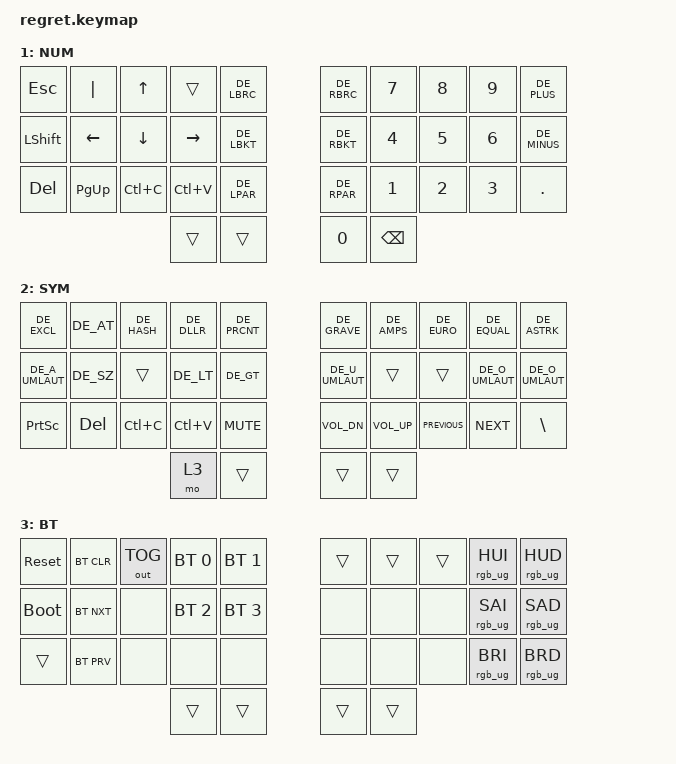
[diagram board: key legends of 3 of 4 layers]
#include <behaviors.dtsi>
#include <dt-bindings/zmk/keys.h>
#include <dt-bindings/zmk/rgb.h>
#include <dt-bindings/zmk/bt.h>
#include <dt-bindings/zmk/outputs.h>
#include <locale/keys_de.h>

#define BASE 0
#define NUM  1
#define NAV  2
#define DE   3


#define COMBO(NAME, BINDINGS, KEYPOS, LAYERS) \
combo_##NAME { \
    timeout-ms = <30>; \
    bindings = <BINDINGS>; \
    key-positions = <KEYPOS>; \
    layers = <LAYERS>; \
};


/ {
    chosen {
          zmk,battery = &vbatt;
    };

    vbatt: vbatt {
            compatible = "zmk,battery-nrf-vddh";
            label = "VBATT";
    };

    combos {
       compatible = "zmk,combos";
        /* Top corners (Q+P) = bootloader */
        combo_boot {
            key-positions = <0 9>;
            bindings = <&bootloader>;
        };
       
       combo_esc {
            timeout-ms = <50>;
            key-positions = <0 1>;
            bindings = <&kp ESC>;
       };
       combo_caps {
            timeout-ms = <50>;
            key-positions = <10 19>;
            bindings = <&caps_word>;
       };
       combo_singlequote {
            timeout-ms = <50>;
            key-positions = <7 8>;
            bindings = <&kp DE_SQT>;
       };
       combo_doublequote {
            timeout-ms = <50>;
            key-positions = <8 9>;
            bindings = <&kp DE_DQT>;
       };
       combo_minus {
            timeout-ms = <50>;
            key-positions = <17 18>;
            bindings = <&kp MINUS>;
       };
       combo_plus {
            timeout-ms = <50>;
            key-positions = <16 17>;
            bindings = <&kp PLUS>;
       };
       combo_equal {
            timeout-ms = <50>;
            key-positions = <27 28>;
            bindings = <&kp EQUAL>;
       };
       combo_underscore {
            timeout-ms = <50>;
            key-positions = <16 17 18>;
            bindings = <&kp DE_UNDER>;
       };
        combo_worddelete {
            timeout-ms = <50>;
            key-positions = <18 19>;
            bindings = <&kp LCTRL(BSPC)>;
       };
        combo_questionmark {
            timeout-ms = <50>;
            key-positions = <28 29>;
            bindings = <&kp DE_QMARK>;
       };
/* Bottom corners = RGB toggle */
        combo_rgb_tog {
            key-positions = <20 29>;
            bindings = <&rgb_ug RGB_TOG>;
        };
    };

    behaviors {
        hl: homerow_mods_left {
            compatible = "zmk,behavior-hold-tap";
            label = "homerow mods left";
            #binding-cells = <2>;
            //flavor = "hold-preferred";
            // flavor = "tap-preferred";
            flavor = "balanced";
            tapping-term-ms = <160>;
            //quick-tap-ms = <100>;
            //hold-while-undecided;
            // global-quick-tap;
            bindings = <&kp>, <&kp>;
            // opposite side hand keys
            hold-trigger-key-positions = <5 6 7 8 9 15 16 17 18 19 25 26 27 28 29 30 31 32 33 34 35>;
        };
        hr: homerow_mods_right {
            compatible = "zmk,behavior-hold-tap";
            label = "homerow mods right";
            #binding-cells = <2>;
            //flavor = "hold-preferred";
            // flavor = "tap-preferred";
            flavor = "balanced";
            tapping-term-ms = <160>;
            //hold-while-undecided;
            //quick-tap-ms = <100>;
            // global-quick-tap;
            bindings = <&kp>, <&kp>;
            // opposite side hand keys
            hold-trigger-key-positions = <0 1 2 3 4 10 11 12 13 14 20 21 22 23 24 30 31 32 33 34 35>;
        };
    };


    keymap {
        compatible = "zmk,keymap";

        default_layer {
// ------------------------------------------------------------------------------------------------------
// |    Q    |    W    |    E    |    R    |    T    |    Y    |    U    |    I    |    O    |    P    |
// |    A    |    S    |    D    |    F    |    G    |    H    |    J    |    K    |    L    |    ;    |
// |    Z    |    X    |    C    |    V    |    B    |    N    |    M    |    ,    |    .    |    /    |
//                               |   ESC   |  SPACE  | RETURN  |   BSPC  |
            bindings = <
                &kp DE_Q       &kp DE_W        &kp DE_E          &kp DE_R               &kp DE_T       &kp DE_Y   &kp DE_U       &kp DE_I       &kp DE_O       &kp DE_P
                &hl LGUI DE_A  &hl LALT DE_S   &hl LCTRL DE_D    &hl LSHFT DE_F         &kp DE_G       &kp DE_H   &hr RSHFT DE_J &hr RCTRL DE_K &hr RALT DE_L  &hr RGUI DE_SEMI
                &kp DE_Z       &kp DE_X        &kp DE_C          &kp DE_V               &kp DE_B       &kp DE_N   &kp DE_M       &kp DE_COMMA   &kp DE_DOT     &kp DE_FSLH
                                               &lt 1 TAB         &kp SPACE              &kp ENTER      &lt 2 BSPC                                              &lt 3 DE_BSLH
            >;
        };
        NUM_layer {
            label= "NUM";
            bindings = <
                &kp ESC      &kp PIPE        &kp UP           &trans             &kp DE_LBRC        &kp DE_RBRC         &kp N7       &kp N8       &kp N9         &kp DE_PLUS
                &kp LSHFT    &kp LEFT        &kp DOWN         &kp RIGHT          &kp DE_LBKT        &kp DE_RBKT         &kp N4       &kp N5       &kp N6         &kp DE_MINUS
                &kp DEL      &kp PAGE_UP     &kp LC(C)        &kp LC(V)          &kp DE_LPAR        &kp DE_RPAR         &kp N1       &kp N2       &kp N3         &kp DOT 
                                                              &trans             &trans             &kp N0              &kp BSPC                                 
            >;
        };

        

        SYM_layer {
            label= "SYM";
            bindings = <
                &kp DE_EXCL     &kp DE_AT     &kp DE_HASH    &kp DE_DLLR       &kp DE_PRCNT         &kp DE_GRAVE    &kp DE_AMPS     &kp DE_EURO     &kp DE_EQUAL      &kp DE_ASTRK         
                &kp DE_A_UMLAUT &kp DE_SZ     &trans         &kp DE_LT         &kp DE_GT            &kp DE_U_UMLAUT &trans          &trans          &kp DE_O_UMLAUT   &kp DE_O_UMLAUT
                &kp PSCRN       &kp DEL       &kp LC(C)      &kp LC(V)         &kp C_MUTE           &kp C_VOL_DN    &kp C_VOL_UP    &kp C_PREVIOUS  &kp C_NEXT        &kp BACKSLASH
                                                             &mo 3             &trans               &trans      &trans                                                
            >;
        };
        BT_layer {
            label= "BT";
            bindings = <
                &sys_reset   &bt BT_CLR  &out OUT_TOG  &bt BT_SEL 0  &bt BT_SEL 1       &trans  &trans  &trans  &rgb_ug RGB_HUI  &rgb_ug RGB_HUD
                &bootloader  &bt BT_NXT  &none         &bt BT_SEL 2  &bt BT_SEL 3       &none   &none   &none   &rgb_ug RGB_SAI  &rgb_ug RGB_SAD
                &trans       &bt BT_PRV  &none         &none         &none              &none   &none   &none   &rgb_ug RGB_BRI  &rgb_ug RGB_BRD
                                                       &trans       &trans              &trans   &trans 
            >;
        };
    };
};
